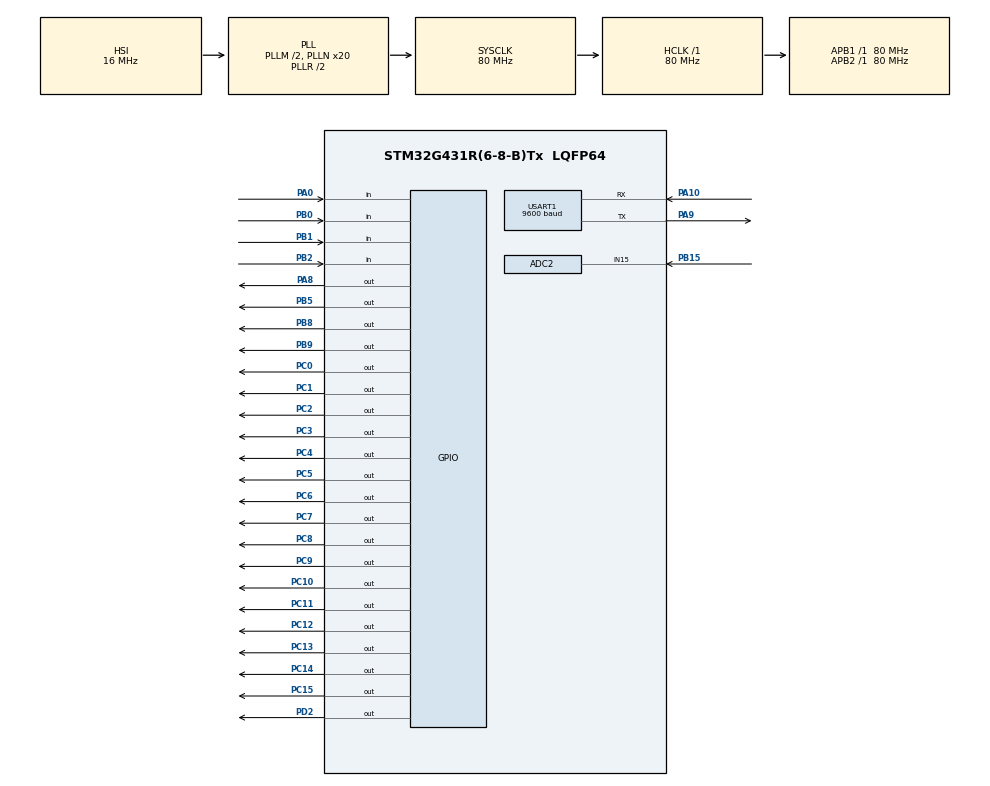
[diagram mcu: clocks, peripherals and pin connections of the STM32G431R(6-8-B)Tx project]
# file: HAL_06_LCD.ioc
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ADC2.Channel-0\#ChannelRegularConversion=ADC_CHANNEL_15
ADC2.NbrOfConversionFlag=1
ADC2.OffsetNumber-0\#ChannelRegularConversion=ADC_OFFSET_NONE
ADC2.OversamplingMode=ENABLE
ADC2.Rank-0\#ChannelRegularConversion=1
ADC2.Ratio=ADC_OVERSAMPLING_RATIO_256
ADC2.RightBitShift=ADC_RIGHTBITSHIFT_4
ADC2.SamplingTime-0\#ChannelRegularConversion=ADC_SAMPLETIME_640CYCLES_5
Mcu.Family=STM32G4
Mcu.Name=STM32G431R(6-8-B)Tx
Mcu.Package=LQFP64
NVIC.PriorityGroup=NVIC_PRIORITYGROUP_4
NVIC.TIM1_TRG_COM_TIM17_IRQn=true\:6\:0\:true\:false\:true\:true\:true\:true
NVIC.TIM6_DAC_IRQn=true\:5\:0\:true\:false\:true\:true\:true\:true
NVIC.USART1_IRQn=true\:5\:0\:true\:false\:true\:true\:true\:true
PA0.GPIO_Mode=GPIO_MODE_INPUT
PA0.GPIO_PuPd=GPIO_PULLUP
PA0.Signal=GPIO_Input
PA10.Mode=Asynchronous
PA10.Signal=USART1_RX
PA13.Mode=Serial_Wire
PA13.Signal=SYS_JTMS-SWDIO
PA14.Mode=Serial_Wire
PA14.Signal=SYS_JTCK-SWCLK
PA8.Signal=GPIO_Output
PA9.Mode=Asynchronous
PA9.Signal=USART1_TX
PB0.GPIO_Mode=GPIO_MODE_INPUT
PB0.GPIO_PuPd=GPIO_PULLUP
PB0.Signal=GPIO_Input
PB1.GPIO_Mode=GPIO_MODE_INPUT
PB1.GPIO_PuPd=GPIO_PULLUP
PB1.Signal=GPIO_Input
PB15.Mode=IN15-Single-Ended
PB15.Signal=ADC2_IN15
PB2.GPIO_Mode=GPIO_MODE_INPUT
PB2.GPIO_PuPd=GPIO_PULLUP
PB2.Signal=GPIO_Input
PB5.Signal=GPIO_Output
PB8-BOOT0.Signal=GPIO_Output
PB9.Signal=GPIO_Output
PC0.Signal=GPIO_Output
PC1.Signal=GPIO_Output
PC10.GPIO_ModeDefaultOutputPP=GPIO_MODE_OUTPUT_PP
PC10.GPIO_PuPd=GPIO_NOPULL
PC10.GPIO_Speed=GPIO_SPEED_FREQ_LOW
PC10.PinState=GPIO_PIN_SET
PC10.Signal=GPIO_Output
PC11.GPIO_ModeDefaultOutputPP=GPIO_MODE_OUTPUT_PP
PC11.GPIO_PuPd=GPIO_NOPULL
PC11.GPIO_Speed=GPIO_SPEED_FREQ_LOW
PC11.PinState=GPIO_PIN_SET
PC11.Signal=GPIO_Output
PC12.GPIO_ModeDefaultOutputPP=GPIO_MODE_OUTPUT_PP
PC12.GPIO_PuPd=GPIO_NOPULL
PC12.GPIO_Speed=GPIO_SPEED_FREQ_LOW
PC12.PinState=GPIO_PIN_SET
PC12.Signal=GPIO_Output
PC13.GPIO_ModeDefaultOutputPP=GPIO_MODE_OUTPUT_PP
PC13.GPIO_PuPd=GPIO_NOPULL
PC13.GPIO_Speed=GPIO_SPEED_FREQ_LOW
PC13.PinState=GPIO_PIN_SET
PC13.Signal=GPIO_Output
PC14-OSC32_IN.GPIO_ModeDefaultOutputPP=GPIO_MODE_OUTPUT_PP
PC14-OSC32_IN.GPIO_PuPd=GPIO_NOPULL
PC14-OSC32_IN.GPIO_Speed=GPIO_SPEED_FREQ_LOW
PC14-OSC32_IN.PinState=GPIO_PIN_SET
PC14-OSC32_IN.Signal=GPIO_Output
PC15-OSC32_OUT.GPIO_ModeDefaultOutputPP=GPIO_MODE_OUTPUT_PP
PC15-OSC32_OUT.GPIO_PuPd=GPIO_NOPULL
PC15-OSC32_OUT.GPIO_Speed=GPIO_SPEED_FREQ_LOW
PC15-OSC32_OUT.PinState=GPIO_PIN_SET
PC15-OSC32_OUT.Signal=GPIO_Output
PC2.Signal=GPIO_Output
PC3.Signal=GPIO_Output
PC4.Signal=GPIO_Output
PC5.Signal=GPIO_Output
PC6.Signal=GPIO_Output
PC7.Signal=GPIO_Output
PC8.GPIO_ModeDefaultOutputPP=GPIO_MODE_OUTPUT_PP
PC8.GPIO_PuPd=GPIO_NOPULL
PC8.GPIO_Speed=GPIO_SPEED_FREQ_LOW
PC8.PinState=GPIO_PIN_SET
PC8.Signal=GPIO_Output
PC9.GPIO_ModeDefaultOutputPP=GPIO_MODE_OUTPUT_PP
PC9.GPIO_PuPd=GPIO_NOPULL
PC9.GPIO_Speed=GPIO_SPEED_FREQ_LOW
PC9.PinState=GPIO_PIN_SET
PC9.Signal=GPIO_Output
PD2.PinState=GPIO_PIN_RESET
PD2.Signal=GPIO_Output
PF0-OSC_IN.Mode=HSE-External-Oscillator
PF0-OSC_IN.Signal=RCC_OSC_IN
PF1-OSC_OUT.Mode=HSE-External-Oscillator
PF1-OSC_OUT.Signal=RCC_OSC_OUT
ProjectManager.HeapSize=0x200
ProjectManager.StackSize=0x400
ProjectManager.TargetToolchain=MDK-ARM V5.27
RCC.ADC12Freq_Value=80000000
RCC.AHBFreq_Value=80000000
RCC.APB1Freq_Value=80000000
RCC.APB1TimFreq_Value=80000000
RCC.APB2Freq_Value=80000000
RCC.APB2TimFreq_Value=80000000
RCC.CortexFreq_Value=80000000
RCC.EXTERNAL_CLOCK_VALUE=12288000
RCC.HCLKFreq_Value=80000000
RCC.HSE_VALUE=24000000
RCC.HSI48_VALUE=48000000
RCC.HSI_VALUE=16000000
RCC.LSE_VALUE=32768
RCC.PLLM=RCC_PLLM_DIV2
RCC.PLLN=20
RCC.SYSCLKFreq_VALUE=80000000
RCC.SYSCLKSource=RCC_SYSCLKSOURCE_PLLCLK
RCC.USBFreq_Value=80000000
RCC.VCOOutputFreq_Value=160000000
TIM17.AutoReloadPreload=TIM_AUTORELOAD_PRELOAD_ENABLE
TIM17.PeriodNoDither=10000-1
TIM17.Prescaler=8000-1
TIM6.AutoReloadPreload=TIM_AUTORELOAD_PRELOAD_ENABLE
TIM6.PeriodNoDither=10000-1
TIM6.Prescaler=80-1
USART1.BaudRate=9600
USART1.VirtualMode-Asynchronous=VM_ASYNC
VP_SYS_VS_DBSignals.Mode=DisableDeadBatterySignals
VP_TIM17_VS_ClockSourceINT.Mode=Enable_Timer
VP_TIM6_VS_ClockSourceINT.Mode=Enable_Timer
board=custom

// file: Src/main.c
/* USER CODE BEGIN Header */
/**
  ******************************************************************************
  * @file           : main.c
  * @brief          : Main program body
  ******************************************************************************
  * @attention
  *
  * <h2><center>&copy; Copyright (c) 2021 STMicroelectronics.
  * All rights reserved.</center></h2>
  *
  * This software component is licensed by ST under BSD 3-Clause license,
  * the "License"; You may not use this file except in compliance with the
  * License. You may obtain a copy of the License at:
  *                        opensource.org/licenses/BSD-3-Clause
  *
  ******************************************************************************
  */
/* USER CODE END Header */
#include "main.h"
#include "adc.h"
#include "tim.h"
#include "usart.h"
#include "gpio.h"

/* USER CODE BEGIN Includes */
#include "my_main.h"
#include "lcd.h"
#include "stdio.h"
/* USER CODE END Includes */

void SystemClock_Config(void);

int main(void)
{

  /* MCU Configuration--------------------------------------------------------*/

  /* Reset of all peripherals, Initializes the Flash interface and the Systick. */
  HAL_Init();

  /* Configure the system clock */
  SystemClock_Config();

  /* Initialize all configured peripherals */
  MX_GPIO_Init();
  MX_ADC2_Init();
  MX_USART1_UART_Init();
  MX_TIM17_Init();
  MX_TIM6_Init();
  /* USER CODE BEGIN 2 */
    setup();

  /* USER CODE END 2 */

  /* Infinite loop */
    while (1)
    {

    /* USER CODE BEGIN 3 */
        loop();
    }
  /* USER CODE END 3 */
}

void SystemClock_Config(void)
{
  RCC_OscInitTypeDef RCC_OscInitStruct = {0};
  RCC_ClkInitTypeDef RCC_ClkInitStruct = {0};

  /** Configure the main internal regulator output voltage
  */
  HAL_PWREx_ControlVoltageScaling(PWR_REGULATOR_VOLTAGE_SCALE1);

  /** Initializes the RCC Oscillators according to the specified parameters
  * in the RCC_OscInitTypeDef structure.
  */
  RCC_OscInitStruct.OscillatorType = RCC_OSCILLATORTYPE_HSI;
  RCC_OscInitStruct.HSIState = RCC_HSI_ON;
  RCC_OscInitStruct.HSICalibrationValue = RCC_HSICALIBRATION_DEFAULT;
  RCC_OscInitStruct.PLL.PLLState = RCC_PLL_ON;
  RCC_OscInitStruct.PLL.PLLSource = RCC_PLLSOURCE_HSI;
  RCC_OscInitStruct.PLL.PLLM = RCC_PLLM_DIV2;
  RCC_OscInitStruct.PLL.PLLN = 20;
  RCC_OscInitStruct.PLL.PLLP = RCC_PLLP_DIV2;
  RCC_OscInitStruct.PLL.PLLQ = RCC_PLLQ_DIV2;
  RCC_OscInitStruct.PLL.PLLR = RCC_PLLR_DIV2;
  if (HAL_RCC_OscConfig(&RCC_OscInitStruct) != HAL_OK)
  {
    Error_Handler();
  }

  /** Initializes the CPU, AHB and APB buses clocks
  */
  RCC_ClkInitStruct.ClockType = RCC_CLOCKTYPE_HCLK|RCC_CLOCKTYPE_SYSCLK
                              |RCC_CLOCKTYPE_PCLK1|RCC_CLOCKTYPE_PCLK2;
  RCC_ClkInitStruct.SYSCLKSource = RCC_SYSCLKSOURCE_PLLCLK;
  RCC_ClkInitStruct.AHBCLKDivider = RCC_SYSCLK_DIV1;
  RCC_ClkInitStruct.APB1CLKDivider = RCC_HCLK_DIV1;
  RCC_ClkInitStruct.APB2CLKDivider = RCC_HCLK_DIV1;

  if (HAL_RCC_ClockConfig(&RCC_ClkInitStruct, FLASH_LATENCY_2) != HAL_OK)
  {
    Error_Handler();
  }
}

void Error_Handler(void)
{
}
